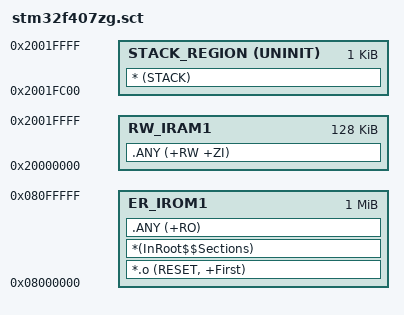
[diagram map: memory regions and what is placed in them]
; *************************************************************
; *** Scatter file for STM32F407ZG (led_serial_tick)        ***
; *** Flash: 1MB @ 0x08000000, SRAM: 128KB @ 0x20000000     ***
; *** STACK 1KB explicitly placed at TOP of RAM             ***
; *************************************************************

LR_IROM1 0x08000000 0x00100000  {
  ER_IROM1 0x08000000 0x00100000  {
    *.o (RESET, +First)
    *(InRoot$$Sections)
    .ANY (+RO)
  }
  RW_IRAM1 0x20000000 0x00020000  {
    .ANY (+RW +ZI)
  }
  STACK_REGION 0x2001FC00 UNINIT 0x00000400  {
    * (STACK)
  }
}
